# f29h85x_lpost_regs register map
Vendor: Texas Instruments
Peripheral module from a debugger description file (folder C29).
Registers are 32-bit, read-write, no defined reset value unless marked. A register's access mark holds for its fields unless they carry their own. Offsets are as the file gives them; lines under a group give offsets from that group; [hi:lo] are bit positions; {n}, {i} and the like mark numbered series; 'fields as' and 'values as' point back to an identical list; <NAME> marks a mode.

## LPOST_REGS — LPOST Registers
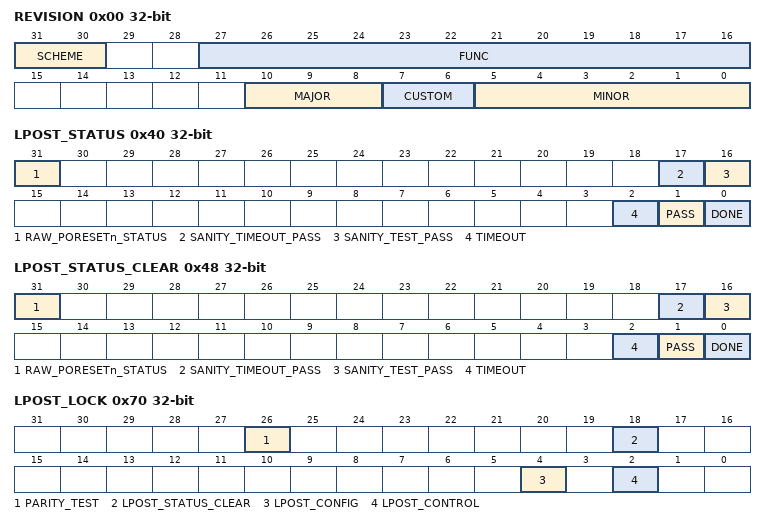
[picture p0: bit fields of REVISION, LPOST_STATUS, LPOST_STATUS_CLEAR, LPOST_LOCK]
0x00 REVISION ro — IP Revision tie-off value
  [31:30] SCHEME — Defines Scheme for Module
  [27:16] FUNC — Functional Release Number
  [10:8] MAJOR — Major Revision Number
  [7:6] CUSTOM — Custom Module Number
  [5:0] MINOR — Minor Revision Number
0x08 LPOST_CONTROL — Register to start the power-on self-test operation.
  [3:0] GO — Start the self-test operation
0x10 LPOST_CONFIG — Register to configure the coverage for the power-on self-test operation.
  [3:0] COVERAGE — Coverage configuration for the power on self-test
0x40 LPOST_STATUS ro — Register indicating the status of power-on self-test operation.
  [31] RAW_PORESETn_STATUS — The bit will indicate RAW PORESETn Status
  [17] SANITY_TIMEOUT_PASS — LPOST timeout test status
  [16] SANITY_TEST_PASS — LPOST sanity test status
  [2] TIMEOUT — LPOST test timeout status
  [1] PASS — LPOST test pass/fail status
  [0] DONE — LPOST completion status.
0x48 LPOST_STATUS_CLEAR — Register to clear the LPOST Status
  [31] RAW_PORESETn_STATUS — Clear bit for RAW_PORESETn_STATUS
  [17] SANITY_TIMEOUT_PASS — SANITY_TIMEOUT_PASS status clear
  [16] SANITY_TEST_PASS — SANITY_TEST_PASS status clear
  [2] TIMEOUT — TIMEOUT status clear
  [1] PASS — PASS status clear
  [0] DONE — DONE status clear
0x70 LPOST_LOCK — Register to lock the LPOST register configurations
  [26] PARITY_TEST — Register lock configuration
  [18] LPOST_STATUS_CLEAR — Register lock configuration
  [4] LPOST_CONFIG — Register lock configuration
  [2] LPOST_CONTROL — Register lock configuration
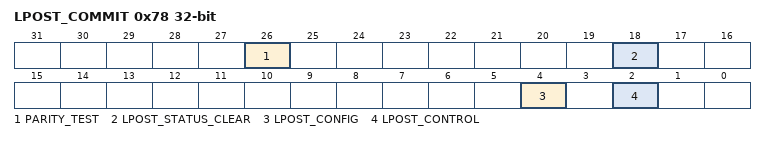
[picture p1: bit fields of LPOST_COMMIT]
0x78 LPOST_COMMIT — Register to commit the LPOST register configuration
  [26] PARITY_TEST — Register commit configuration
  [18] LPOST_STATUS_CLEAR — Register lock configuration
  [4] LPOST_CONFIG — Register commit configuration
  [2] LPOST_CONTROL — Register commit configuration
